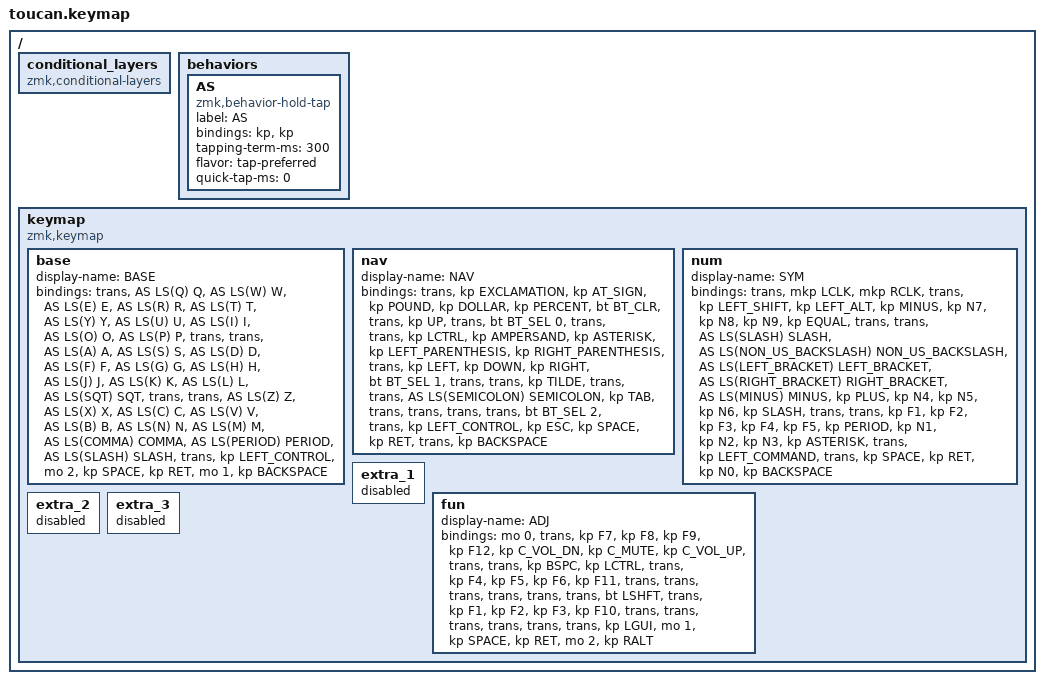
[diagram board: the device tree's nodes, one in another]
#include <behaviors.dtsi>
#include <dt-bindings/zmk/bt.h>
#include <dt-bindings/zmk/keys.h>
#include <dt-bindings/zmk/pointing.h>

#define BASE 0
#define NAV  1
#define SYM  2
#define ADJ  3

/ {
    conditional_layers { compatible = "zmk,conditional-layers"; };

    behaviors {
        AS: AS {
            compatible = "zmk,behavior-hold-tap";
            label = "AS";
            bindings = <&kp>, <&kp>;

            #binding-cells = <2>;
            tapping-term-ms = <300>;
            flavor = "tap-preferred";
            quick-tap-ms = <0>;
        };
    };

    keymap {
        compatible = "zmk,keymap";

        base {
            display-name = "BASE";
            bindings = <
&trans  &AS LS(Q) Q  &AS LS(W) W  &AS LS(E) E  &AS LS(R) R  &AS LS(T) T  &AS LS(Y) Y  &AS LS(U) U  &AS LS(I) I  &AS LS(O) O  &AS LS(P) P  &trans  &trans  &AS LS(A) A  &AS LS(S) S  &AS LS(D) D  &AS LS(F) F  &AS LS(G) G  &AS LS(H) H  &AS LS(J) J  &AS LS(K) K  &AS LS(L) L  &AS LS(SQT) SQT  &trans  &trans  &AS LS(Z) Z  &AS LS(X) X  &AS LS(C) C  &AS LS(V) V  &AS LS(B) B  &AS LS(N) N  &AS LS(M) M  &AS LS(COMMA) COMMA  &AS LS(PERIOD) PERIOD  &AS LS(SLASH) SLASH  &trans  &kp LEFT_CONTROL  &mo 2  &kp SPACE  &kp RET  &mo 1  &kp BACKSPACE
            >;
        };

        nav {
            display-name = "NAV";
            bindings = <
&trans  &kp EXCLAMATION  &kp AT_SIGN  &kp POUND  &kp DOLLAR  &kp PERCENT  &bt BT_CLR  &trans  &kp UP  &trans  &bt BT_SEL 0  &trans  &trans  &kp LCTRL  &kp AMPERSAND  &kp ASTERISK  &kp LEFT_PARENTHESIS  &kp RIGHT_PARENTHESIS  &trans  &kp LEFT  &kp DOWN  &kp RIGHT  &bt BT_SEL 1  &trans  &trans  &kp TILDE  &trans  &trans  &AS LS(SEMICOLON) SEMICOLON  &kp TAB  &trans  &trans  &trans  &trans  &bt BT_SEL 2  &trans  &kp LEFT_CONTROL  &kp ESC  &kp SPACE  &kp RET  &trans  &kp BACKSPACE
            >;
        };

        num {
            display-name = "SYM";
            bindings = <
&trans  &mkp LCLK  &mkp RCLK  &trans  &kp LEFT_SHIFT  &kp LEFT_ALT  &kp MINUS  &kp N7  &kp N8  &kp N9  &kp EQUAL  &trans  &trans  &AS LS(SLASH) SLASH  &AS LS(NON_US_BACKSLASH) NON_US_BACKSLASH  &AS LS(LEFT_BRACKET) LEFT_BRACKET  &AS LS(RIGHT_BRACKET) RIGHT_BRACKET  &AS LS(MINUS) MINUS  &kp PLUS  &kp N4  &kp N5  &kp N6  &kp SLASH  &trans  &trans  &kp F1  &kp F2  &kp F3  &kp F4  &kp F5  &kp PERIOD  &kp N1  &kp N2  &kp N3  &kp ASTERISK  &trans  &kp LEFT_COMMAND  &trans  &kp SPACE  &kp RET  &kp N0  &kp BACKSPACE
            >;
        };

        extra_1 { status = "reserved"; };

        fun {
            display-name = "ADJ";
            bindings = <
&mo 0  &trans  &kp F7  &kp F8  &kp F9  &kp F12  &kp C_VOL_DN  &kp C_MUTE  &kp C_VOL_UP  &trans  &trans  &kp BSPC  &kp LCTRL  &trans  &kp F4  &kp F5  &kp F6  &kp F11  &trans  &trans  &trans  &trans  &trans  &trans  &bt LSHFT  &trans  &kp F1  &kp F2  &kp F3  &kp F10  &trans  &trans  &trans  &trans  &trans  &trans  &kp LGUI  &mo 1  &kp SPACE  &kp RET  &mo 2  &kp RALT
            >;
        };

        extra_2 { status = "reserved"; };

        extra_3 { status = "reserved"; };
    };
};
